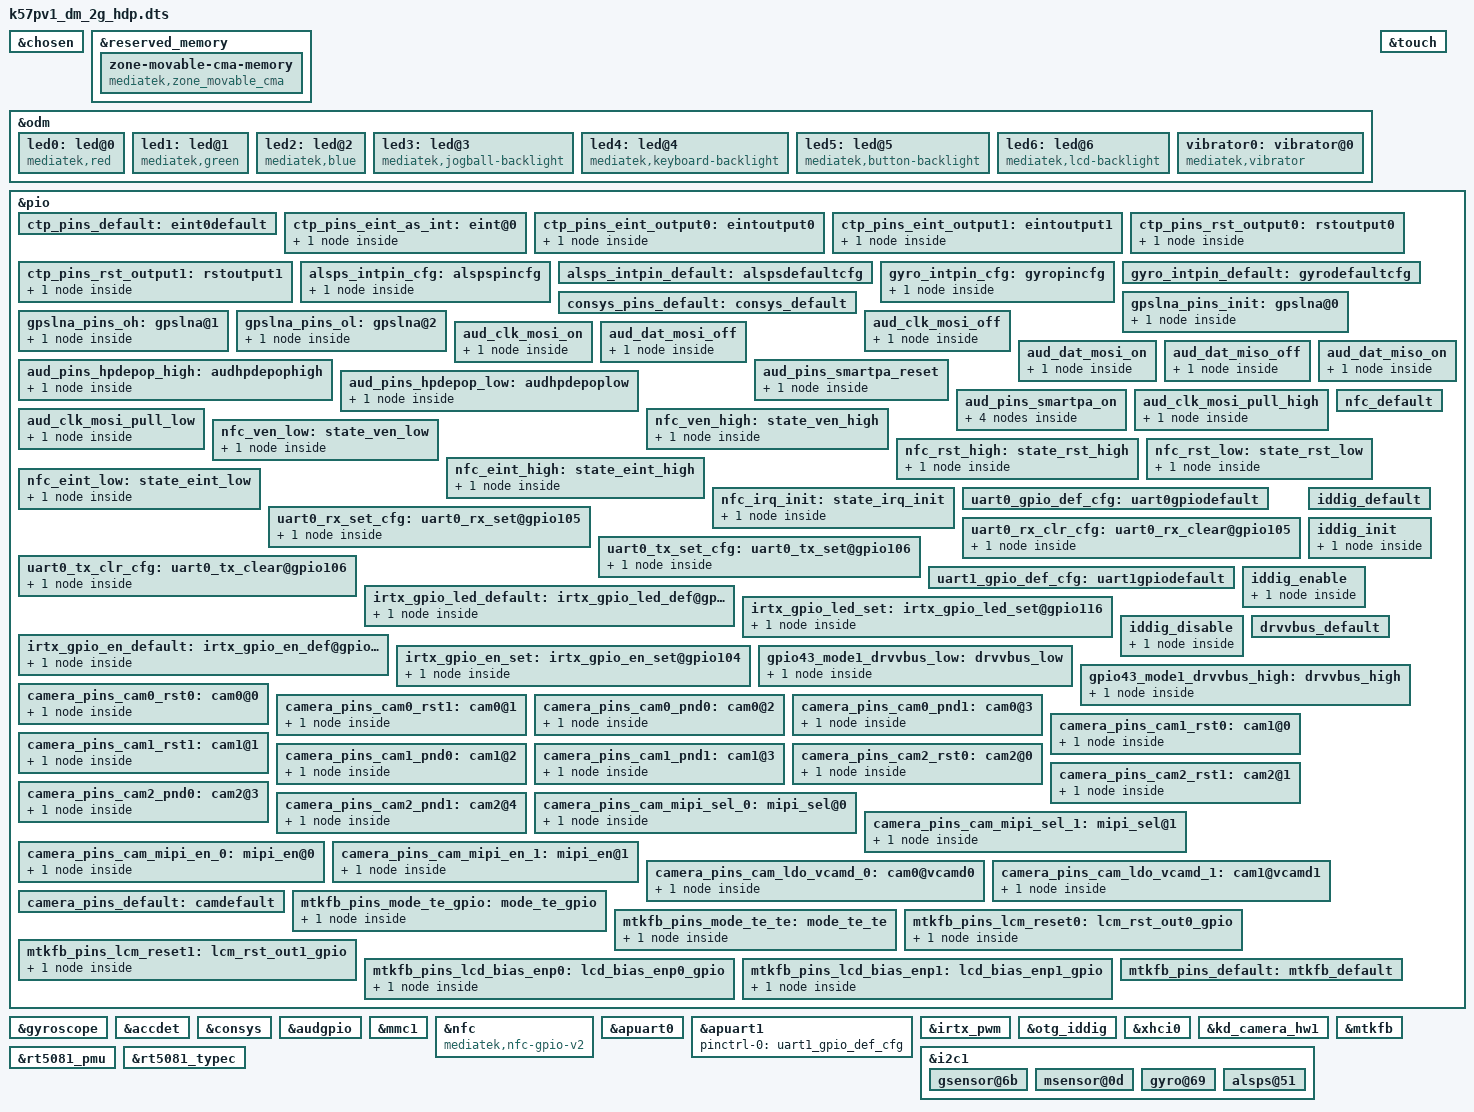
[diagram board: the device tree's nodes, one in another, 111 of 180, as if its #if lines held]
/*
 * Mediatek's k57pv1_dm_2g_hdp SoC device tree source
 *
 * Copyright (C) 2017 MediaTek Inc.
 *
 * This program is free software; you can redistribute it and/or modify
 * it under the terms of the GNU General Public License version 2 as
 * published by the Free Software Foundation.
 *
 * This program is distributed in the hope that it will be useful,
 * but WITHOUT ANY WARRANTY; without even the implied warranty of
 * MERCHANTABILITY or FITNESS FOR A PARTICULAR PURPOSE.
 * See http://www.gnu.org/licenses/gpl-2.0.html for more details.
 */

#include <generated/autoconf.h>
/dts-v1/;

#ifdef CONFIG_MTK_DTBO_FEATURE
/plugin/;
#include <dt-bindings/interrupt-controller/irq.h>
#include <dt-bindings/interrupt-controller/arm-gic.h>
#include <dt-bindings/mmc/mt6757-msdc.h>
#include <dt-bindings/pinctrl/mt6757-pinfunc.h>
#else
#include "mt6757.dts"
#endif


/* chosen */
&chosen {
	/* fpga may has no lk, we need to specify display info here */
	/* fb buffer is reserved using this dts by memory node above */
	atag,videolfb-fb_base_h = <0x0>;
	atag,videolfb-fb_base_l = <0x5e605000>;
	atag,videolfb-islcmfound = <1>;
	/* because no lk, so lcm is not inited */
	atag,videolfb-islcm_inited = <0>;
	atag,videolfb-fps= <6000>;
	atag,videolfb-vramSize= <0x017bb000>;
	atag,videolfb-lcmname= "nt35695_fhd_dsi_cmd_truly_nt50358_drv";
};

&reserved_memory {
	#address-cells = <2>;
	#size-cells = <2>;
	ranges;

	zone-movable-cma-memory {
		compatible = "mediatek,zone_movable_cma";
		size = <0 0xffc00000>;
		/* 256MB alignment */
		alignment = <0 0x10000000>;
		alloc-ranges = <0 0xc0000000 1 0x00000000>;
	};
};

&odm {
	led0:led@0 {
		compatible = "mediatek,red";
		led_mode = <0>;
		data = <1>;
		pwm_config = <0 0 0 0 0>;
	};
	led1:led@1 {
		compatible = "mediatek,green";
		led_mode = <0>;
		data = <1>;
		pwm_config = <0 0 0 0 0>;
	};
	led2:led@2 {
		compatible = "mediatek,blue";
		led_mode = <0>;
		data = <1>;
		pwm_config = <0 0 0 0 0>;
	};
	led3:led@3 {
		compatible = "mediatek,jogball-backlight";
		led_mode = <0>;
		data = <1>;
		pwm_config = <0 0 0 0 0>;
	};
	led4:led@4 {
		compatible = "mediatek,keyboard-backlight";
		led_mode = <0>;
		data = <1>;
		pwm_config = <0 0 0 0 0>;
	};
	led5:led@5 {
		compatible = "mediatek,button-backlight";
		led_mode = <0>;
		data = <1>;
		pwm_config = <0 0 0 0 0>;
	};
	led6:led@6 {
		compatible = "mediatek,lcd-backlight";
		led_mode = <5>;
		data = <1>;
		pwm_config = <0 3 0 0 0>;
	};
	vibrator0:vibrator@0 {
		compatible = "mediatek,vibrator";
		vib_timer = <25>;
		vib_limit = <9>;
		vib_vol= <9>;
	};


};

/* TOUCH start */
&touch {
	tpd-resolution = <1080 1920>;
	use-tpd-button = <0>;
	tpd-key-num = <3>;
	tpd-key-local= <139 172 158 0>;
	tpd-key-dim-local = <90 883 100 40 230 883 100 40 370 883 100 40 0 0 0 0>;
	tpd-max-touch-num = <5>;
	tpd-filter-enable = <1>;
	tpd-filter-pixel-density = <146>;
	tpd-filter-custom-prameters = <0 0 0 0 0 0 0 0 0 0 0 0>;
	tpd-filter-custom-speed = <0 0 0>;
	pinctrl-names = "default", "state_eint_as_int", "state_eint_output0", "state_eint_output1",
		"state_rst_output0", "state_rst_output1";
	pinctrl-0 = <&ctp_pins_default>;
	pinctrl-1 = <&ctp_pins_eint_as_int>;
	pinctrl-2 = <&ctp_pins_eint_output0>;
	pinctrl-3 = <&ctp_pins_eint_output1>;
	pinctrl-4 = <&ctp_pins_rst_output0>;
	pinctrl-5 = <&ctp_pins_rst_output1>;
	status = "okay";
};
&pio {
	ctp_pins_default: eint0default {
	};
	ctp_pins_eint_as_int: eint@0 {
		pins_cmd_dat {
			pinmux = <PINMUX_GPIO1__FUNC_GPIO1>;
			slew-rate = <0>;
			bias-disable;
		};
	};
	ctp_pins_eint_output0: eintoutput0 {
		pins_cmd_dat {
			pinmux = <PINMUX_GPIO1__FUNC_GPIO1>;
			slew-rate = <1>;
			output-low;
		};
	};
	ctp_pins_eint_output1: eintoutput1 {
		pins_cmd_dat {
			pinmux = <PINMUX_GPIO1__FUNC_GPIO1>;
			slew-rate = <1>;
			output-high;
		};
	};
	ctp_pins_rst_output0: rstoutput0 {
		pins_cmd_dat {
			pinmux = <PINMUX_GPIO10__FUNC_GPIO10>;
			slew-rate = <1>;
			output-low;
		};
	};
	ctp_pins_rst_output1: rstoutput1 {
		pins_cmd_dat {
			pinmux = <PINMUX_GPIO10__FUNC_GPIO10>;
			slew-rate = <1>;
			output-high;
		};
	};
};
/* TOUCH end */

/* sensor gpio standization */
&pio {
	alsps_intpin_cfg: alspspincfg {

		pins_cmd_dat {
			pinmux = <PINMUX_GPIO6__FUNC_GPIO6>;
			slew-rate = <0>;
			bias-pull-up = <00>;
		};
	};

	alsps_intpin_default: alspsdefaultcfg {

	};

	gyro_intpin_cfg: gyropincfg {

		pins_cmd_dat {
			pinmux = <PINMUX_GPIO4__FUNC_GPIO4>;
			slew-rate = <0>;
			bias-pull-down = <00>;
		};
	};

	gyro_intpin_default: gyrodefaultcfg {

	};
};


&gyroscope {
	pinctrl-names = "pin_default", "pin_cfg";
	pinctrl-0 = <&gyro_intpin_default>;
	pinctrl-1 = <&gyro_intpin_cfg>;
	status = "okay";
};
/* sensor end */

/* accdet start */
&accdet {
		/* accdet micbias voltage: 0x07,2.7v;0x05,2.5v;0x02,1.9v */
		accdet-mic-vol = <7>;
		headset-mode-setting = <0x500 0x500 1 0x1F0 0x800 0x800 0x20>;
		accdet-plugout-debounce = <1>;
		/*1:ACC mode, 2:low cost without in bias, 6:low cost with in bias*/
		accdet-mic-mode = <2>;
		/* eint_level_trigger: 8,LEVEL_LOW(default);4,LEVEL_HIGH;others,LEVEL_LOW */
		headset-eint-level-pol = <8>;
		/*0--MD_MAX--UP_MAX--DW_MAX*/
		headset-three-key-threshold = <0 80 220 400>;
		headset-three-key-threshold-CDD = <0 121 192 600>;
		/*0--MD_MAX--VOICE_MAX--UP_MAX--DW_MAX*/
		headset-four-key-threshold = <0 58 121 192 400>;
		/* ACCDET GPIO standardization ACC mode no use */
};
/* accdet end*/

/* CONSYS GPIO standardization */
&pio {
	consys_pins_default: consys_default {
	};
	gpslna_pins_init: gpslna@0 {
		pins_cmd_dat {
			pinmux = <PINMUX_GPIO114__FUNC_GPIO114>;
			slew-rate = <0>;
			bias-disable;
			output-low;
		};
	};
	gpslna_pins_oh: gpslna@1 {
		pins_cmd_dat {
			pinmux = <PINMUX_GPIO114__FUNC_GPIO114>;
			slew-rate = <1>;
			output-high;
		};
	};
	gpslna_pins_ol: gpslna@2 {
		pins_cmd_dat {
			pinmux = <PINMUX_GPIO114__FUNC_GPIO114>;
			slew-rate = <1>;
			output-low;
		};
	};
};
&consys {
	pinctrl-names = "default", "gps_lna_state_init", "gps_lna_state_oh", "gps_lna_state_ol";
	pinctrl-0 = <&consys_pins_default>;
	pinctrl-1 = <&gpslna_pins_init>;
	pinctrl-2 = <&gpslna_pins_oh>;
	pinctrl-3 = <&gpslna_pins_ol>;
	status = "okay";
};
/* CONSYS end */

/* AUDIO GPIO standardization */
&audgpio {
	pinctrl-names = "aud_clk_mosi_off",
			"aud_clk_mosi_on",
			"aud_dat_mosi_off",
			"aud_dat_mosi_on",
			"aud_dat_miso_off",
			"aud_dat_miso_on",
			"hpdepop-pullhigh",
			"hpdepop-pulllow",
			"aud_smartpa_reset",
			"aud_smartpa_on",
			"aud_clk_mosi_pull_high",
			"aud_clk_mosi_pull_low";
	pinctrl-0 = <&aud_clk_mosi_off>;
	pinctrl-1 = <&aud_clk_mosi_on>;
	pinctrl-2 = <&aud_dat_mosi_off>;
	pinctrl-3 = <&aud_dat_mosi_on>;
	pinctrl-4 = <&aud_dat_miso_off>;
	pinctrl-5 = <&aud_dat_miso_on>;
	pinctrl-6 = <&aud_pins_hpdepop_high>;
	pinctrl-7 = <&aud_pins_hpdepop_low>;
	pinctrl-8 = <&aud_pins_smartpa_reset>;
	pinctrl-9 = <&aud_pins_smartpa_on>;
	pinctrl-10 = <&aud_clk_mosi_pull_high>;
	pinctrl-11 = <&aud_clk_mosi_pull_low>;
	status = "okay";
};

&pio {
	aud_clk_mosi_off: aud_clk_mosi_off {
		pins_cmd0_dat {
			pinmux = <PINMUX_GPIO149__FUNC_GPIO149>;
		};
	};

	aud_clk_mosi_on: aud_clk_mosi_on {
		pins_cmd0_dat {
			pinmux = <PINMUX_GPIO149__FUNC_AUD_CLK_MOSI>;
		};
	};

	aud_dat_mosi_off: aud_dat_mosi_off {
		pins_cmd1_dat {
			pinmux = <PINMUX_GPIO150__FUNC_GPIO150>;
			slew-rate = <0>;
			bias-pull-up;
		};
	};

	aud_dat_mosi_on: aud_dat_mosi_on {
		pins_cmd1_dat {
			pinmux = <PINMUX_GPIO150__FUNC_AUD_DAT_MOSI>;
		};
	};

	aud_dat_miso_off: aud_dat_miso_off {
		pins_cmd2_dat {
			pinmux = <PINMUX_GPIO151__FUNC_GPIO151>;
		};
	};

	aud_dat_miso_on: aud_dat_miso_on {
		pins_cmd2_dat {
			pinmux = <PINMUX_GPIO151__FUNC_AUD_DAT_MISO>;
		};
	};

	aud_pins_hpdepop_high: audhpdepophigh {
		pins_cmd_dat {
			pinmux = <PINMUX_GPIO24__FUNC_GPIO24>;
			slew-rate = <1>;
			output-high;
		};
	};

	aud_pins_hpdepop_low: audhpdepoplow {
		pins_cmd_dat {
			pinmux = <PINMUX_GPIO24__FUNC_GPIO24>;
			slew-rate = <1>;
			output-low;
		};
	};

	aud_pins_smartpa_reset: aud_pins_smartpa_reset {
		pins_cmd0_dat {
			pinmux = <PINMUX_GPIO190__FUNC_GPIO190>;
		};
	};

	aud_pins_smartpa_on: aud_pins_smartpa_on {
		pins_cmd0_dat {
			pinmux = <PINMUX_GPIO16__FUNC_I2S0_DI>;
		};
		pins_cmd1_dat {
			pinmux = <PINMUX_GPIO26__FUNC_I2S3_BCK>;
		};
		pins_cmd2_dat {
			pinmux = <PINMUX_GPIO27__FUNC_I2S3_LRCK>;
		};
		pins_cmd3_dat {
			pinmux = <PINMUX_GPIO28__FUNC_I2S3_DO>;
		};
	};

	aud_clk_mosi_pull_high: aud_clk_mosi_pull_high {
		pins_cmd_dat {
			pinmux = <PINMUX_GPIO149__FUNC_GPIO149>;
			slew-rate = <1>;
			output-high;
		};
	};

	aud_clk_mosi_pull_low: aud_clk_mosi_pull_low {
		pins_cmd_dat {
			pinmux = <PINMUX_GPIO149__FUNC_GPIO149>;
			slew-rate = <1>;
			output-low;
		};
	};
};
/* AUDIO end */

&mmc1 {
	status = "okay";
};

&nfc {
	compatible = "mediatek,nfc-gpio-v2";
	gpio-ven = <&pio 15 0>;
	gpio-rst = <&pio 25 0>;
	gpio-eint = <&pio 14 0>;
	gpio-irq = <&pio 13 0>;
	gpio-osc = <&pio 99 0>;
	pinctrl-names = "default", "ven_high", "ven_low", "rst_high", "rst_low",
	"eint_high", "eint_low", "irq_init";
	pinctrl-0 = <&nfc_default>;
	pinctrl-1 = <&nfc_ven_high>;
	pinctrl-2 = <&nfc_ven_low>;
	pinctrl-3 = <&nfc_rst_high>;
	pinctrl-4 = <&nfc_rst_low>;
	pinctrl-5 = <&nfc_eint_high>;
	pinctrl-6 = <&nfc_eint_low>;
	pinctrl-7 = <&nfc_irq_init>;
	status = "okay";
};

/* NFC GPIO standardization */
&pio {
	nfc_default: nfc_default {

	};

	nfc_ven_high: state_ven_high {
		pins_cmd_dat {
			pinmux = <PINMUX_GPIO15__FUNC_GPIO15>;
			slew-rate = <1>;
			output-high;
		};
	};

	nfc_ven_low: state_ven_low {
		pins_cmd_dat {
			pinmux = <PINMUX_GPIO15__FUNC_GPIO15>;
			slew-rate = <1>;
			output-low;
		};
	};

	nfc_rst_high: state_rst_high {
		pins_cmd_dat {
			pinmux = <PINMUX_GPIO25__FUNC_GPIO25>;
			slew-rate = <1>;
			output-high;
		};
	};

	nfc_rst_low: state_rst_low {
		pins_cmd_dat {
			pinmux = <PINMUX_GPIO25__FUNC_GPIO25>;
			slew-rate = <1>;
			output-low;
		};
	};

	nfc_eint_high: state_eint_high {
		pins_cmd_dat {
			pinmux = <PINMUX_GPIO14__FUNC_GPIO14>;
			slew-rate = <1>;
			output-high;
		};
	};

	nfc_eint_low: state_eint_low {
		pins_cmd_dat {
			pinmux = <PINMUX_GPIO14__FUNC_GPIO14>;
			slew-rate = <1>;
			output-low;
		};
	};

	nfc_irq_init: state_irq_init {
		pins_cmd_dat {
			pinmux = <PINMUX_GPIO13__FUNC_GPIO13>;
			slew-rate = <0>;
			bias-pull-down = <00>;
		};
	};
};
/* NFC end */

/* UART GPIO */

&apuart0 {
	pinctrl-names = "uart0_gpio_default",
			"uart0_rx_set",
			"uart0_rx_clear",
			"uart0_tx_set",
			"uart0_tx_clear";
	pinctrl-0 = <&uart0_gpio_def_cfg>;
	pinctrl-1 = <&uart0_rx_set_cfg>;
	pinctrl-2 = <&uart0_rx_clr_cfg>;
	pinctrl-3 = <&uart0_tx_set_cfg>;
	pinctrl-4 = <&uart0_tx_clr_cfg>;
	status = "okay";
};

&apuart1 {
	pinctrl-names = "uart1_gpio_default";
	pinctrl-0 = <&uart1_gpio_def_cfg>;
	status = "okay";
};

&pio {
	/* UART GPIO Settings - Start */
	/* UART0: rx set, rx clear, tx clear, tx clear*/
	uart0_gpio_def_cfg:uart0gpiodefault {

	};
	uart0_rx_set_cfg:uart0_rx_set@gpio105 {
		pins_cmd_dat {
			pinmux = <PINMUX_GPIO105__FUNC_URXD0>;
		};
	};
	uart0_rx_clr_cfg:uart0_rx_clear@gpio105  {
		pins_cmd_dat {
			pinmux = <PINMUX_GPIO105__FUNC_GPIO105>;
			slew-rate = <1>;
			output-high;
		};
	};
	uart0_tx_set_cfg:uart0_tx_set@gpio106  {
		pins_cmd_dat {
			pinmux = <PINMUX_GPIO106__FUNC_UTXD0>;
		};
	};
	uart0_tx_clr_cfg:uart0_tx_clear@gpio106  {
		pins_cmd_dat {
			pinmux = <PINMUX_GPIO106__FUNC_GPIO106>;
			slew-rate = <1>;
			output-high;
		};
	};
	/* UART1: GPIO default setting*/
	uart1_gpio_def_cfg:uart1gpiodefault {

	};
};/* UART GPIO end */

/* IRTX GPIO end */
&irtx_pwm {
	pinctrl-names = "irtx_gpio_led_default",
			"irtx_gpio_led_set",
			"irtx_gpio_en_default",
			"irtx_gpio_en_set";

	pinctrl-0 = <&irtx_gpio_led_default>;
	pinctrl-1 = <&irtx_gpio_led_set>;
	pinctrl-2 = <&irtx_gpio_en_default>;
	pinctrl-3 = <&irtx_gpio_en_set>;
	status = "okay";
};
&pio {
	/* IRTX GPIO Settings -Start */
	/* default: GPIO0, output, high */
	irtx_gpio_led_default:irtx_gpio_led_def@gpio116 {
		pins_cmd_dat {
			pinmux = <PINMUX_GPIO116__FUNC_GPIO116>;
			slew-rate = <1>;
			bias-disable;
			output-low;
			input-schmitt-enable = <0>;
		};
	};

	irtx_gpio_led_set:irtx_gpio_led_set@gpio116 {
		pins_cmd_dat {
			pinmux = <PINMUX_GPIO116__FUNC_PWM_C>;
			slew-rate = <1>;
			output-high;
		};
	};

	irtx_gpio_en_default:irtx_gpio_en_def@gpio104 {
		pins_cmd_dat {
			pinmux = <PINMUX_GPIO104__FUNC_GPIO104>;
			slew-rate = <1>;
			bias-disable;
			output-low;
			input-schmitt-enable = <0>;
		};
	};

	irtx_gpio_en_set:irtx_gpio_en_set@gpio104 {
		pins_cmd_dat {
			pinmux = <PINMUX_GPIO104__FUNC_GPIO104>;
			slew-rate = <1>;
			output-high;
		};
	};


}; /* IRTX GPIO Settings -End */

&pio {
	iddig_default: iddig_default {
	};
	iddig_init: iddig_init {
		pins_cmd_dat {
			pinmux = <PINMUX_GPIO42__FUNC_IDDIG>;
			input-enable;
			slew-rate = <0>;
			bias-pull-up;
		};
	};
	iddig_enable: iddig_enable {
		pins_cmd_dat {
			pinmux = <PINMUX_GPIO42__FUNC_IDDIG>;
			input-enable;
			slew-rate = <0>;
			bias-pull-up;
		};
	};
	iddig_disable: iddig_disable {
		pins_cmd_dat {
			pinmux = <PINMUX_GPIO42__FUNC_GPIO42>;
			input-disable;
			slew-rate = <1>;
			output-low;
		};
	};
};

&pio {
	drvvbus_default: drvvbus_default {
	};

	gpio43_mode1_drvvbus_low: drvvbus_low {
		pins_cmd_dat {
			pinmux = <PINMUX_GPIO43__FUNC_USB_DRVVBUS>;
			slew-rate = <1>;
			output-low;
		};
	};

	gpio43_mode1_drvvbus_high: drvvbus_high {
		pins_cmd_dat {
			pinmux = <PINMUX_GPIO43__FUNC_USB_DRVVBUS>;
			slew-rate = <1>;
			output-high;
		};
	};
};

&otg_iddig {
	pinctrl-names = "iddig_default", "iddig_init", "iddig_enable", "iddig_disable";
	pinctrl-0 = <&iddig_default>;
	pinctrl-1 = <&iddig_init>;
	pinctrl-2 = <&iddig_enable>;
	pinctrl-3 = <&iddig_disable>;
	status = "okay";
};

&xhci0 {
	pinctrl-names = "drvvbus_default", "drvvbus_low", "drvvbus_high";
	pinctrl-0 = <&drvvbus_default>;
	pinctrl-1 = <&gpio43_mode1_drvvbus_low>;
	pinctrl-2 = <&gpio43_mode1_drvvbus_high>;
	status = "okay";
};
/* CAMERA GPIO standardization */
&pio {
	camera_pins_cam0_rst0: cam0@0 {
		pins_cmd_dat {
			pinmux = <PINMUX_GPIO110__FUNC_GPIO110>;
			slew-rate = <1>; /*direction 0:in, 1:out*/
			output-low;/*direction out used only. output_low or high*/
		};
	};
	camera_pins_cam0_rst1: cam0@1 {
		pins_cmd_dat {
			pinmux = <PINMUX_GPIO110__FUNC_GPIO110>;
			slew-rate = <1>;
			output-high;
		};
	};
	camera_pins_cam0_pnd0: cam0@2 {
		pins_cmd_dat {
			pinmux = <PINMUX_GPIO107__FUNC_GPIO107>;
			slew-rate = <1>;
			output-low;
		};
	};
	camera_pins_cam0_pnd1: cam0@3 {
		pins_cmd_dat {
			pinmux = <PINMUX_GPIO107__FUNC_GPIO107>;
			slew-rate = <1>;
			output-high;
		};
	};
	camera_pins_cam1_rst0: cam1@0 {
		pins_cmd_dat {
			pinmux = <PINMUX_GPIO111__FUNC_GPIO111>;
			slew-rate = <1>; /*direction 0:in, 1:out*/
			output-low;/*direction out used only. output_low or high*/
		};
	};
	camera_pins_cam1_rst1: cam1@1 {
		pins_cmd_dat {
			pinmux = <PINMUX_GPIO111__FUNC_GPIO111>;
			slew-rate = <1>;
			output-high;
		};
	};
	camera_pins_cam1_pnd0: cam1@2 {
		pins_cmd_dat {
			pinmux = <PINMUX_GPIO108__FUNC_GPIO108>;
			slew-rate = <1>;
			output-low;
		};
	};
	camera_pins_cam1_pnd1: cam1@3 {
		pins_cmd_dat {
			pinmux = <PINMUX_GPIO108__FUNC_GPIO108>;
			slew-rate = <1>;
			output-high;
		};
	};
	camera_pins_cam2_rst0: cam2@0 {
		pins_cmd_dat {
			pinmux = <PINMUX_GPIO86__FUNC_GPIO86>;
			slew-rate = <1>;
			output-low;
		};
	};
	camera_pins_cam2_rst1: cam2@1 {
		pins_cmd_dat {
			pinmux = <PINMUX_GPIO86__FUNC_GPIO86>;
			slew-rate = <1>;
			output-high;
		};
	};
	camera_pins_cam2_pnd0: cam2@3 {
		pins_cmd_dat {
			pinmux = <PINMUX_GPIO85__FUNC_GPIO85>;
			slew-rate = <1>;
			output-low;
		};
	};
	camera_pins_cam2_pnd1: cam2@4 {
		pins_cmd_dat {
			pinmux = <PINMUX_GPIO85__FUNC_GPIO85>;
			slew-rate = <1>;
			output-high;
		};
	};
	camera_pins_cam_mipi_sel_0: mipi_sel@0 {
		pins_cmd_dat {
			pinmux = <PINMUX_GPIO84__FUNC_GPIO84>;
			slew-rate = <1>;
			output-low;
		};
	};
	camera_pins_cam_mipi_sel_1: mipi_sel@1 {
		pins_cmd_dat {
			pinmux = <PINMUX_GPIO84__FUNC_GPIO84>;
			slew-rate = <1>;
			output-high;
		};
	};
	camera_pins_cam_mipi_en_0: mipi_en@0 {
		pins_cmd_dat {
			pinmux = <PINMUX_GPIO83__FUNC_GPIO83>;
			slew-rate = <1>;
			output-low;
		};
	};
	camera_pins_cam_mipi_en_1: mipi_en@1 {
		pins_cmd_dat {
			pinmux = <PINMUX_GPIO83__FUNC_GPIO83>;
			slew-rate = <1>;
			output-high;
		};
	};
	camera_pins_cam_ldo_vcamd_0: cam0@vcamd0 {
		pins_cmd_dat {
			pinmux = <PINMUX_GPIO23__FUNC_GPIO23>;
			slew-rate = <1>;
			output-low;
		};
	};
	camera_pins_cam_ldo_vcamd_1: cam1@vcamd1 {
		pins_cmd_dat {
			pinmux = <PINMUX_GPIO23__FUNC_GPIO23>;
			slew-rate = <1>;
			output-high;
		};
	};
	camera_pins_default: camdefault {
	};

};

&kd_camera_hw1 {
	pinctrl-names = "default",
			"cam0_rst0", "cam0_rst1", "cam0_pnd0", "cam0_pnd1",
			"cam1_rst0", "cam1_rst1", "cam1_pnd0", "cam1_pnd1",
			"cam2_rst0", "cam2_rst1", "cam2_pnd0", "cam2_pnd1",
			"cam_mipi_switch_sel_0", "cam_mipi_switch_sel_1",
			"cam_mipi_switch_en_0", "cam_mipi_switch_en_1",
			"cam_ldo_vcamd_0", "cam_ldo_vcamd_1";

	pinctrl-0 = <&camera_pins_default>;
	pinctrl-1 = <&camera_pins_cam0_rst0>;
	pinctrl-2 = <&camera_pins_cam0_rst1>;
	pinctrl-3 = <&camera_pins_cam0_pnd0>;
	pinctrl-4 = <&camera_pins_cam0_pnd1>;
	pinctrl-5 = <&camera_pins_cam1_rst0>;
	pinctrl-6 = <&camera_pins_cam1_rst1>;
	pinctrl-7 = <&camera_pins_cam1_pnd0>;
	pinctrl-8 = <&camera_pins_cam1_pnd1>;
	pinctrl-9 = <&camera_pins_cam2_rst0>;
	pinctrl-10 = <&camera_pins_cam2_rst1>;
	pinctrl-11 = <&camera_pins_cam2_pnd0>;
	pinctrl-12 = <&camera_pins_cam2_pnd1>;
	pinctrl-13 = <&camera_pins_cam_mipi_sel_0>;
	pinctrl-14 = <&camera_pins_cam_mipi_sel_1>;
	pinctrl-15 = <&camera_pins_cam_mipi_en_0>;
	pinctrl-16 = <&camera_pins_cam_mipi_en_1>;
	pinctrl-17 = <&camera_pins_cam_ldo_vcamd_0>;
	pinctrl-18 = <&camera_pins_cam_ldo_vcamd_1>;
	status = "okay";

};
/* CAMERA GPIO end */

/* DISPSYS GPIO standardization */
&pio {

	mtkfb_pins_mode_te_gpio: mode_te_gpio {
		pins_cmd_dat {
			pinmux = <PINMUX_GPIO44__FUNC_GPIO44>;
		};
	};

	mtkfb_pins_mode_te_te: mode_te_te {
		pins_cmd_dat {
			pinmux = <PINMUX_GPIO44__FUNC_DSI_TE>;
		};
	};

	mtkfb_pins_lcm_reset0: lcm_rst_out0_gpio {
		pins_cmd_dat {
			pinmux = <PINMUX_GPIO158__FUNC_LCM_RST>;
			slew-rate = <1>;
			output-low;
		};
	};

	mtkfb_pins_lcm_reset1: lcm_rst_out1_gpio {
		pins_cmd_dat {
			pinmux = <PINMUX_GPIO158__FUNC_LCM_RST>;
			slew-rate = <1>;
			output-high;
		};
	};

	mtkfb_pins_lcd_bias_enp0: lcd_bias_enp0_gpio {
		pins_cmd_dat {
			pinmux = <PINMUX_GPIO12__FUNC_GPIO12>;
			slew-rate = <1>;
			output-low;
		};
	};

	mtkfb_pins_lcd_bias_enp1: lcd_bias_enp1_gpio {
		pins_cmd_dat {
			pinmux = <PINMUX_GPIO12__FUNC_GPIO12>;
			slew-rate = <1>;
			output-high;
		};
	};

	mtkfb_pins_default: mtkfb_default {
	};

};

&mtkfb {
	pinctrl-names = "default", "mode_te_gpio", "mode_te_te", "lcm_rst_out0_gpio",
	"lcm_rst_out1_gpio", "lcd_bias_enp0_gpio", "lcd_bias_enp1_gpio";
	pinctrl-0 = <&mtkfb_pins_default>;
	pinctrl-1 = <&mtkfb_pins_mode_te_gpio>;
	pinctrl-2 = <&mtkfb_pins_mode_te_te>;
	pinctrl-3 = <&mtkfb_pins_lcm_reset0>;
	pinctrl-4 = <&mtkfb_pins_lcm_reset1>;
	pinctrl-5 = <&mtkfb_pins_lcd_bias_enp0>;
	pinctrl-6 = <&mtkfb_pins_lcd_bias_enp1>;
	partial-update = <0>;
	status = "okay";
};/* DISPSYS GPIO standardization end */
#ifdef CONFIG_MFD_RT5081_PMU
&rt5081_pmu {
	rt,intr_gpio_num = <101>; /* direct defined GPIO num */
	rt,intr_gpio = <&pio 101 0x0>;
};
#endif
&rt5081_typec {
	rt5081pd,intr_gpio_num = <8>; /* direct defined GPIO num */
	rt5081pd,intr_gpio = <&pio 8 0x0>;
};


&i2c1 {

	gsensor@6b {
		i2c_num	= <1>;
		i2c_addr = <0x6a 0 0 0>;
		direction = <7>;
		power_id = <0xffff>;
		power_vol = <0>;
		firlen = <16>;
		is_batch_supported = <1>;
	};

	msensor@0d {
		i2c_num = <1>;
		i2c_addr = <0x0d 0 0 0>;
		direction = <7>;
		power_id = <0xffff>;
		power_vol = <0>;
		is_batch_supported = <0>;
	};

	gyro@69 {
		pinctrl-names = "pin_default", "pin_cfg";
		pinctrl-0 = <&gyro_intpin_default>;
		pinctrl-1 = <&gyro_intpin_cfg>;
		status = "okay";
		/* customization */
		i2c_num = <1>;
		i2c_addr = <0x69 0 0 0>;
		direction = <7>;
		power_id = <0xffff>;
		power_vol = <0>;
		firlen = <0>;
		is_batch_supported = <0>;
	};

	alsps@51 {
		pinctrl-names = "pin_default", "pin_cfg";
		pinctrl-0 = <&alsps_intpin_default>;
		pinctrl-1 = <&alsps_intpin_cfg>;
		status = "okay";
		i2c_num = <1>;
		i2c_addr = <0x51 0 0 0>;
		polling_mode_ps = <0>;
		polling_mode_als = <1>;
		power_id = <0xffff>;
		power_vol = <0>;
		als_level = <0 328 861 1377 3125 7721 7767 12621 23062 28430 33274 47116 57694 57694 65535>;
		als_value = <0 133 304 502 1004 2005 3058 5005 8008 10010 12000 16000 20000 20000 20000 20000>;
		ps_threshold_high = <26>;
		ps_threshold_low = <21>;
		is_batch_supported_ps = <0>;
		is_batch_supported_als = <0>;
	};
};

#include <k57pv1_dm_2g_hdp/cust.dtsi>
/*End of this file, DO NOT ADD ANYTHING HERE*/

